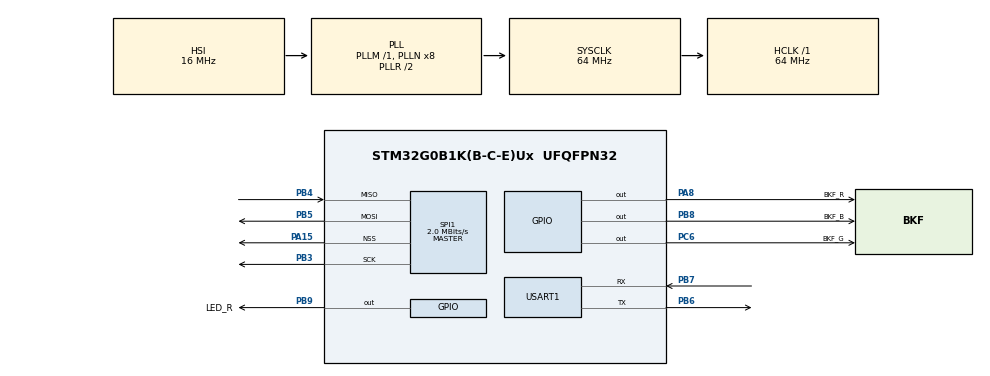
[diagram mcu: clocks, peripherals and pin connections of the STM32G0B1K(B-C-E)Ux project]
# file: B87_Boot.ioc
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Dma.Request0=USART1_RX
Dma.Request1=USART1_TX
Dma.Request2=SPI1_TX
Dma.Request3=SPI1_RX
Dma.SPI1_RX.3.Direction=DMA_PERIPH_TO_MEMORY
Dma.SPI1_RX.3.EventEnable=DISABLE
Dma.SPI1_RX.3.Instance=DMA1_Channel6
Dma.SPI1_RX.3.MemDataAlignment=DMA_MDATAALIGN_BYTE
Dma.SPI1_RX.3.MemInc=DMA_MINC_ENABLE
Dma.SPI1_RX.3.Mode=DMA_NORMAL
Dma.SPI1_RX.3.PeriphDataAlignment=DMA_PDATAALIGN_BYTE
Dma.SPI1_RX.3.PeriphInc=DMA_PINC_DISABLE
Dma.SPI1_RX.3.Polarity=HAL_DMAMUX_REQ_GEN_RISING
Dma.SPI1_RX.3.Priority=DMA_PRIORITY_LOW
Dma.SPI1_RX.3.RequestNumber=1
Dma.SPI1_RX.3.SignalID=NONE
Dma.SPI1_RX.3.SyncEnable=DISABLE
Dma.SPI1_RX.3.SyncPolarity=HAL_DMAMUX_SYNC_NO_EVENT
Dma.SPI1_RX.3.SyncRequestNumber=1
Dma.SPI1_RX.3.SyncSignalID=NONE
Dma.SPI1_TX.2.Direction=DMA_MEMORY_TO_PERIPH
Dma.SPI1_TX.2.EventEnable=DISABLE
Dma.SPI1_TX.2.Instance=DMA1_Channel5
Dma.SPI1_TX.2.MemDataAlignment=DMA_MDATAALIGN_BYTE
Dma.SPI1_TX.2.MemInc=DMA_MINC_ENABLE
Dma.SPI1_TX.2.Mode=DMA_NORMAL
Dma.SPI1_TX.2.PeriphDataAlignment=DMA_PDATAALIGN_BYTE
Dma.SPI1_TX.2.PeriphInc=DMA_PINC_DISABLE
Dma.SPI1_TX.2.Polarity=HAL_DMAMUX_REQ_GEN_RISING
Dma.SPI1_TX.2.Priority=DMA_PRIORITY_LOW
Dma.SPI1_TX.2.RequestNumber=1
Dma.SPI1_TX.2.SignalID=NONE
Dma.SPI1_TX.2.SyncEnable=DISABLE
Dma.SPI1_TX.2.SyncPolarity=HAL_DMAMUX_SYNC_NO_EVENT
Dma.SPI1_TX.2.SyncRequestNumber=1
Dma.SPI1_TX.2.SyncSignalID=NONE
Dma.USART1_RX.0.Direction=DMA_PERIPH_TO_MEMORY
Dma.USART1_RX.0.EventEnable=DISABLE
Dma.USART1_RX.0.Instance=DMA1_Channel1
Dma.USART1_RX.0.MemDataAlignment=DMA_MDATAALIGN_BYTE
Dma.USART1_RX.0.MemInc=DMA_MINC_ENABLE
Dma.USART1_RX.0.Mode=DMA_NORMAL
Dma.USART1_RX.0.PeriphDataAlignment=DMA_PDATAALIGN_BYTE
Dma.USART1_RX.0.PeriphInc=DMA_PINC_DISABLE
Dma.USART1_RX.0.Polarity=HAL_DMAMUX_REQ_GEN_RISING
Dma.USART1_RX.0.Priority=DMA_PRIORITY_LOW
Dma.USART1_RX.0.RequestNumber=1
Dma.USART1_RX.0.SignalID=NONE
Dma.USART1_RX.0.SyncEnable=DISABLE
Dma.USART1_RX.0.SyncPolarity=HAL_DMAMUX_SYNC_NO_EVENT
Dma.USART1_RX.0.SyncRequestNumber=1
Dma.USART1_RX.0.SyncSignalID=NONE
Dma.USART1_TX.1.Direction=DMA_MEMORY_TO_PERIPH
Dma.USART1_TX.1.EventEnable=DISABLE
Dma.USART1_TX.1.Instance=DMA1_Channel2
Dma.USART1_TX.1.MemDataAlignment=DMA_MDATAALIGN_BYTE
Dma.USART1_TX.1.MemInc=DMA_MINC_ENABLE
Dma.USART1_TX.1.Mode=DMA_NORMAL
Dma.USART1_TX.1.PeriphDataAlignment=DMA_PDATAALIGN_BYTE
Dma.USART1_TX.1.PeriphInc=DMA_PINC_DISABLE
Dma.USART1_TX.1.Polarity=HAL_DMAMUX_REQ_GEN_RISING
Dma.USART1_TX.1.Priority=DMA_PRIORITY_LOW
Dma.USART1_TX.1.RequestNumber=1
Dma.USART1_TX.1.SignalID=NONE
Dma.USART1_TX.1.SyncEnable=DISABLE
Dma.USART1_TX.1.SyncPolarity=HAL_DMAMUX_SYNC_NO_EVENT
Dma.USART1_TX.1.SyncRequestNumber=1
Dma.USART1_TX.1.SyncSignalID=NONE
Mcu.Family=STM32G0
Mcu.Name=STM32G0B1K(B-C-E)Ux
Mcu.Package=UFQFPN32
NVIC.DMA1_Ch4_7_DMA2_Ch1_5_DMAMUX1_OVR_IRQn=true\:0\:0\:false\:false\:true\:false\:true\:true
NVIC.DMA1_Channel1_IRQn=true\:0\:0\:false\:false\:true\:false\:true\:true
NVIC.DMA1_Channel2_3_IRQn=true\:0\:0\:false\:false\:true\:false\:true\:true
NVIC.USART1_IRQn=true\:0\:0\:false\:false\:true\:true\:true\:true
PA13.Mode=Serial_Wire
PA13.Signal=SYS_SWDIO
PA14-BOOT0.Mode=Serial_Wire
PA14-BOOT0.Signal=SYS_SWCLK
PA15.Mode=NSS_Signal_Hard_Output
PA15.Signal=SPI1_NSS
PA8.GPIO_Label=BKF_R
PA8.PinState=GPIO_PIN_SET
PA8.Signal=GPIO_Output
PB3.Mode=Full_Duplex_Master
PB3.Signal=SPI1_SCK
PB4.Mode=Full_Duplex_Master
PB4.Signal=SPI1_MISO
PB5.Mode=Full_Duplex_Master
PB5.Signal=SPI1_MOSI
PB6.GPIO_Speed=GPIO_SPEED_FREQ_VERY_HIGH
PB6.Mode=Asynchronous
PB6.Signal=USART1_TX
PB7.GPIO_Speed=GPIO_SPEED_FREQ_VERY_HIGH
PB7.Mode=Asynchronous
PB7.Signal=USART1_RX
PB8.GPIO_Label=BKF_B
PB8.PinState=GPIO_PIN_SET
PB8.Signal=GPIO_Output
PB9.GPIO_Label=LED_R
PB9.Signal=GPIO_Output
PC6.GPIO_Label=BKF_G
PC6.PinState=GPIO_PIN_SET
PC6.Signal=GPIO_Output
ProjectManager.HeapSize=0x200
ProjectManager.StackSize=0x400
ProjectManager.TargetToolchain=MDK-ARM V5.32
RCC.ADCFreq_Value=64000000
RCC.AHBFreq_Value=64000000
RCC.CortexFreq_Value=64000000
RCC.EXTERNAL_CLOCK_VALUE=48000
RCC.HCLKFreq_Value=64000000
RCC.HSE_VALUE=8000000
RCC.HSI48_VALUE=48000000
RCC.HSI_VALUE=16000000
RCC.LSE_VALUE=32768
RCC.SYSCLKFreq_VALUE=64000000
RCC.SYSCLKSource=RCC_SYSCLKSOURCE_PLLCLK
RCC.USBFreq_Value=48000000
RCC.VCOOutputFreq_Value=128000000
SPI1.BaudRatePrescaler=SPI_BAUDRATEPRESCALER_32
SPI1.CalculateBaudRate=2.0 MBits/s
SPI1.Direction=SPI_DIRECTION_2LINES
SPI1.Mode=SPI_MODE_MASTER
SPI1.VirtualNSS=VM_NSSHARD
SPI1.VirtualType=VM_MASTER
USART1.VirtualMode-Asynchronous=VM_ASYNC
VP_SYS_VS_DBSignals.Mode=DisableDeadBatterySignals
board=custom

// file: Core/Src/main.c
/* USER CODE BEGIN Header */
/**
  ******************************************************************************
  * @file           : main.c
  * @brief          : Main program body
  ******************************************************************************
  * @attention
  *
  * Copyright (c) 2026 STMicroelectronics.
  * All rights reserved.
  *
  * This software is licensed under terms that can be found in the LICENSE file
  * in the root directory of this software component.
  * If no LICENSE file comes with this software, it is provided AS-IS.
  *
  ******************************************************************************
  */
/* USER CODE END Header */
#include "main.h"
#include "dma.h"
#include "spi.h"
#include "usart.h"
#include "gpio.h"

/* USER CODE BEGIN Includes */
#include "Usart_Func.h"
#include "iap.h"
#include "stmflash.h"
#include "Flash_Protection.h"
#include "W25Qxx.h"
/* USER CODE END Includes */

void SystemClock_Config(void);

int main(void)
{

  /* MCU Configuration--------------------------------------------------------*/

  /* Reset of all peripherals, Initializes the Flash interface and the Systick. */
  HAL_Init();

  /* Configure the system clock */
  SystemClock_Config();

  /* Initialize all configured peripherals */
  MX_GPIO_Init();
  MX_DMA_Init();
  MX_USART1_UART_Init();
  MX_SPI1_Init();
  /* USER CODE BEGIN 2 */

	//Flash_Protection();

	W25QXX_Init();          //W25Q SPI Flash Init
	IAP_BootLoad_Init();    //IAP Init

	//USART1->CR1 |= (1<<4);  //Enable IDLE interrupt

  /* USER CODE END 2 */

  /* Infinite loop */
  /* USER CODE BEGIN WHILE */
  while (1)
  {
    iap_monition();

    /* USER CODE END WHILE */

  }
}

void SystemClock_Config(void)
{
  RCC_OscInitTypeDef RCC_OscInitStruct = {0};
  RCC_ClkInitTypeDef RCC_ClkInitStruct = {0};

  /** Configure the main internal regulator output voltage
  */
  HAL_PWREx_ControlVoltageScaling(PWR_REGULATOR_VOLTAGE_SCALE1);

  /** Initializes the RCC Oscillators according to the specified parameters
  * in the RCC_OscInitTypeDef structure.
  */
  RCC_OscInitStruct.OscillatorType = RCC_OSCILLATORTYPE_HSI;
  RCC_OscInitStruct.HSIState = RCC_HSI_ON;
  RCC_OscInitStruct.HSIDiv = RCC_HSI_DIV1;
  RCC_OscInitStruct.HSICalibrationValue = RCC_HSICALIBRATION_DEFAULT;
  RCC_OscInitStruct.PLL.PLLState = RCC_PLL_ON;
  RCC_OscInitStruct.PLL.PLLSource = RCC_PLLSOURCE_HSI;
  RCC_OscInitStruct.PLL.PLLM = RCC_PLLM_DIV1;
  RCC_OscInitStruct.PLL.PLLN = 8;
  RCC_OscInitStruct.PLL.PLLP = RCC_PLLP_DIV2;
  RCC_OscInitStruct.PLL.PLLQ = RCC_PLLQ_DIV2;
  RCC_OscInitStruct.PLL.PLLR = RCC_PLLR_DIV2;
  if (HAL_RCC_OscConfig(&RCC_OscInitStruct) != HAL_OK)
  {
    Error_Handler();
  }

  /** Initializes the CPU, AHB and APB buses clocks
  */
  RCC_ClkInitStruct.ClockType = RCC_CLOCKTYPE_HCLK|RCC_CLOCKTYPE_SYSCLK
                              |RCC_CLOCKTYPE_PCLK1;
  RCC_ClkInitStruct.SYSCLKSource = RCC_SYSCLKSOURCE_PLLCLK;
  RCC_ClkInitStruct.AHBCLKDivider = RCC_SYSCLK_DIV1;
  RCC_ClkInitStruct.APB1CLKDivider = RCC_HCLK_DIV1;

  if (HAL_RCC_ClockConfig(&RCC_ClkInitStruct, FLASH_LATENCY_2) != HAL_OK)
  {
    Error_Handler();
  }
}

void Error_Handler(void)
{
  __disable_irq();
  while (1)
  {
  }
}
